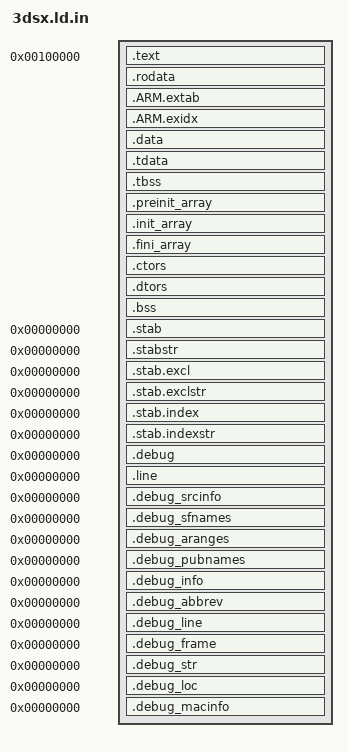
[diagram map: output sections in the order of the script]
/*--------------------------------------------------------------------------------
	This Source Code Form is subject to the terms of the Mozilla Public License,
	v. 2.0. If a copy of the MPL was not distributed with this file, You can
	obtain one at https://mozilla.org/MPL/2.0/.
--------------------------------------------------------------------------------*/
OUTPUT_FORMAT("elf32-littlearm", "elf32-bigarm", "elf32-littlearm")
OUTPUT_ARCH(arm)
ENTRY(_start)

PHDRS
{
	code   PT_LOAD FLAGS(5) /* Read | Execute */;
	rodata PT_LOAD FLAGS(4) /* Read */;
	data   PT_LOAD FLAGS(6) /* Read | Write */;
}

SECTIONS
{
	/* =========== CODE section =========== */

	PROVIDE(__start__ = 0x100000);
	. = __start__;

	.text ALIGN(0x1000) :
	{
		/* .init */
		KEEP( *(.crt0) )
		KEEP( *(.init) )
		. = ALIGN(4);

		/* .text: hot walker span first (by function section name, -ffunction-sections), in call order of one draw; 16 KB or less (ARM11 L1I). Hot set: wcen_mac01 opsplit, S103. Then cold code (.text.unlikely.*), then the rest. */
		/* PERF2 step 4: by rate. Per op (the walk loop, its state ops and the triangle path), then per draw (the batch close in call order); C3Di_UpdateContext and
		 * C3D_UpdateUniforms left the span (about 2 calls per frame after PERF2 step 1). Span bytes: python 3ds/tools/hotset.py (M2, HC0). */
		*(.text.nd_walk_run .text.g2_same .text.pm_gbi_run .text.gv_params_calc .text.gv_epoch_enter .text.gv_tri .text.draw_tri .text.nd_geom_vtx)
		*(.text.tex_op .text.tex_op.* .text.ensure_tile .text.ensure_tile.* .text.load_mtx .text.sync_combine .text.pm_gpu_gappend .text.pm_gpu_gtrip)
		*(.text.flush_impl .text.flush_impl_body .text.flush_draw .text.nd_raw_native .text.nd_native_submit .text.nd_tmpl_build .text.nd_emit_draw .text.ndunit_after .text.sync_combine_work) /* A5: the batch close in call order */
		*libcitro3d.a:*(.text.C3D_TexBind)
		*(.text.unlikely.*)
		*(.text)
		*(.text.*)
		*(.glue_7)
		*(.glue_7t)
		*(.stub)
		*(.gnu.warning)
		*(.gnu.linkonce.t*)
		. = ALIGN(4);

		/* .fini */
		KEEP( *(.fini) )
		. = ALIGN(4);
	} : code

	/* =========== RODATA section =========== */

	. = ALIGN(0x1000);

	.rodata :
	{
		*(.rodata)
		*(.roda)
		*(.rodata.*)
		*all.rodata*(*)
		*(.gnu.linkonce.r*)
		SORT(CONSTRUCTORS)
		. = ALIGN(4);
		__tdata_align = .;
		LONG (ALIGNOF(.tdata));
		. = ALIGN(4);
	} : rodata

	.ARM.extab : { *(.ARM.extab* .gnu.linkonce.armextab.*) } : rodata
	__exidx_start = .;
	.ARM.exidx : { *(.ARM.exidx* .gnu.linkonce.armexidx.*) } : rodata
	__exidx_end = .;

	/* =========== DATA section =========== */

	. = ALIGN(0x1000);

	/* MS01: blocks of the map statics (generated, see tools/gen_map_restore.py). The rest of this file is devkitPro 3dsx.ld. */
	INCLUDE @MS_LD_DIR@/map_restore.ld

	.data :
	{
		/* CF5: hot scalar block first, 32-byte aligned (see PM_HOTD in include/pm_port.h) */
		. = ALIGN(32);
		*(.data.pmhot)
		*(.data)
		*(.data.*)
		*(.gnu.linkonce.d*)
		CONSTRUCTORS
		. = ALIGN(4);
	} : data

	.tdata : ALIGN(4)
	{
		__tdata_lma = .;
		*(.tdata)
		*(.tdata.*)
		*(.gnu.linkonce.td.*)
		. = ALIGN(4);
		__tdata_lma_end = .;
	} : data

	.tbss : ALIGN(4)
	{
		*(.tbss)
		*(.tbss.*)
		*(.gnu.linkonce.tb.*)
		*(.tcommon)
		. = ALIGN(4);
	} : data

	/*
    __tdata_align_val = ABSOLUTE(ALIGNOF(.tdata));
    __tdata_size = ABSOLUTE(SIZEOF(.tdata));
    __tbss_align = ABSOLUTE(ALIGNOF(.tbss));
    __tbss_size = ABSOLUTE(SIZEOF(.tbss));
	*/

	.preinit_array ALIGN(4) :
	{
		PROVIDE (__preinit_array_start = .);
		KEEP (*(.preinit_array))
		PROVIDE (__preinit_array_end = .);
	} : data

	.init_array ALIGN(4) :
	{
		PROVIDE (__init_array_start = .);
		KEEP (*(SORT(.init_array.*)))
		KEEP (*(.init_array))
		PROVIDE (__init_array_end = .);
	} : data

	.fini_array ALIGN(4) :
	{
		PROVIDE (__fini_array_start = .);
		KEEP (*(.fini_array))
		KEEP (*(SORT(.fini_array.*)))
		PROVIDE (__fini_array_end = .);
	} : data

	.ctors ALIGN(4) :
	{
		KEEP (*crtbegin.o(.ctors)) /* MUST be first -- GCC requires it */
		KEEP (*(EXCLUDE_FILE (*crtend.o) .ctors))
		KEEP (*(SORT(.ctors.*)))
		KEEP (*(.ctors))
	} : data

	.dtors ALIGN(4) :
	{
		KEEP (*crtbegin.o(.dtors))
		KEEP (*(EXCLUDE_FILE (*crtend.o) .dtors))
		KEEP (*(SORT(.dtors.*)))
		KEEP (*(.dtors))
	} : data

	__bss_start__ = .;
	.bss ALIGN(4) :
	{
		/* MEM-A: map .bss blocks first (NOBITS, generated by tools/gen_map_restore.py) */
		INCLUDE @MS_LD_DIR@/map_restore_bss.ld
		*(.dynbss)
		*(.bss)
		*(.bss.*)
		*(.gnu.linkonce.b*)
		*(COMMON)

		/* Reserve space for the TLS segment of the main thread.
		   We need (__tls_start - 8) to be aligned the same as .tdata, to account for
		   the 8-byte ARM TLS header. Since the header is not actually used for
		   ARM_TLS_LE32 relocation, we just fake it by subtracting 8 from the data
		   offset.
		 */
		. = 8 + ABSOLUTE(ALIGN(ABSOLUTE(. - 8), MAX(ALIGNOF(.tdata), ALIGNOF(.tbss))));
		__tls_start = .;
		. += SIZEOF(.tdata);

        /* Ensure the alignment of .tbss is accounted for in the total size,
           since SIZEOF(.tdata) doesn't include any padding before .tbss.
         */
        . = ALIGN(ALIGNOF(.tbss));
        . += SIZEOF(.tbss);
		__tls_end = .;
	} : data
	__bss_end__ = .;

	__end__ = ABSOLUTE(.) ;

	/* ==================
	   ==== Metadata ====
	   ================== */

	/* Discard sections that difficult post-processing */
	/DISCARD/ : { *(.group .comment .note) }

	/* Stabs debugging sections. */
	.stab          0 : { *(.stab) }
	.stabstr       0 : { *(.stabstr) }
	.stab.excl     0 : { *(.stab.excl) }
	.stab.exclstr  0 : { *(.stab.exclstr) }
	.stab.index    0 : { *(.stab.index) }
	.stab.indexstr 0 : { *(.stab.indexstr) }

	/* DWARF debug sections.
	   Symbols in the DWARF debugging sections are relative to the beginning
	   of the section so we begin them at 0. */

	/* DWARF 1 */
	.debug          0 : { *(.debug) }
	.line           0 : { *(.line) }

	/* GNU DWARF 1 extensions */
	.debug_srcinfo  0 : { *(.debug_srcinfo) }
	.debug_sfnames  0 : { *(.debug_sfnames) }

	/* DWARF 1.1 and DWARF 2 */
	.debug_aranges  0 : { *(.debug_aranges) }
	.debug_pubnames 0 : { *(.debug_pubnames) }

	/* DWARF 2 */
	.debug_info     0 : { *(.debug_info) }
	.debug_abbrev   0 : { *(.debug_abbrev) }
	.debug_line     0 : { *(.debug_line) }
	.debug_frame    0 : { *(.debug_frame) }
	.debug_str      0 : { *(.debug_str) }
	.debug_loc      0 : { *(.debug_loc) }
	.debug_macinfo  0 : { *(.debug_macinfo) }
}
